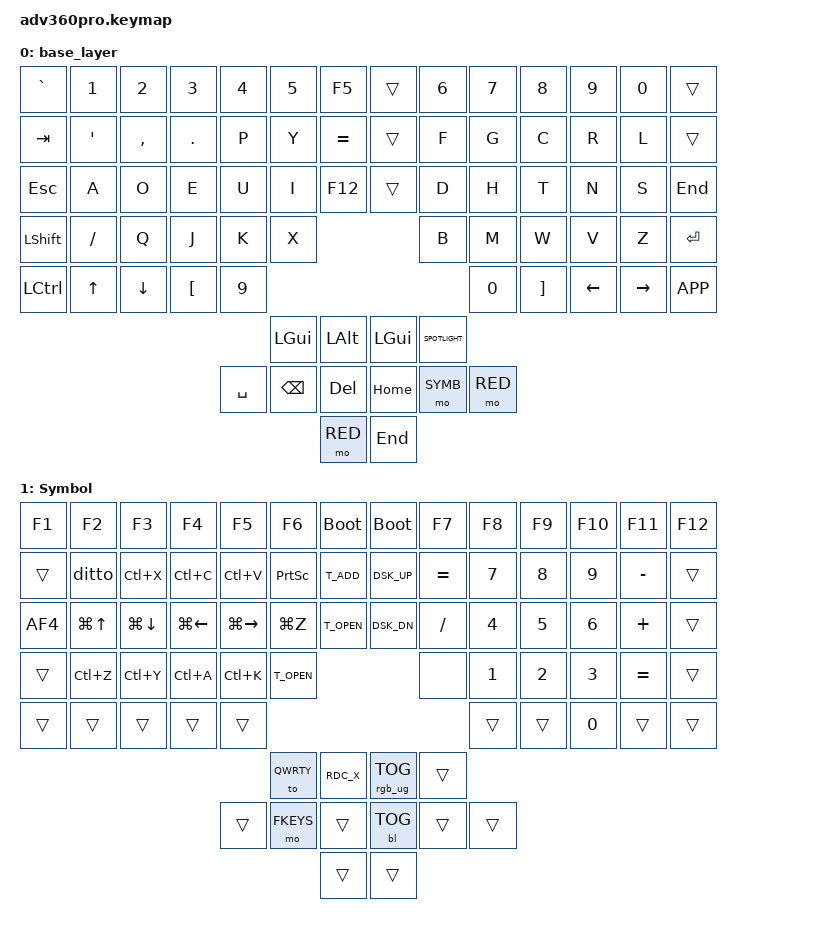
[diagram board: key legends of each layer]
#include <behaviors.dtsi>
#include <dt-bindings/zmk/keys.h>
#include <dt-bindings/zmk/bt.h>
#include <dt-bindings/zmk/outputs.h>
#include <dt-bindings/zmk/rgb.h>
#include <dt-bindings/zmk/backlight.h>

/* definitions for mouse layer */
#include "mouse.dtsi"

#define ___ &trans

#define BOOTL &bootloader

#define W_UP &kp LG(UP)
#define W_DWN &kp LG(DOWN)
#define W_LFT &kp LG(LEFT)
#define W_RGT &kp LG(RIGHT)

#define BASE 0
#define RED 1
#define SYMB 2
#define FKEYS 3
#define QWRTY 4

#define QWERTY 0
#define COLEMAK 1
#define KEYPAD 2
#define FN 3
#define MOD 4
#define MS 5

#define RGBTGL &rgb_ug RGB_TOG
#define BTTGL &bl BL_TOG

/ {
    /* remove unused keys from layout and move thumb cluster to bottom */
    chosen {
        zmk,matrix_transform = &urobs_transform;
    };    
    behaviors {
      #include "macros/macros.dtsi"
    };

    keymap {
        compatible = "zmk,keymap";
        base_layer {
            bindings = <
                &kp GRAVE &kp N1    &kp N2    &kp N3    &kp N4    &kp N5    &kp F5         ___       &kp N6    &kp N7    &kp N8    &kp N9    &kp N0    ___
                &kp TAB   &kp SQT   &kp COMMA &kp PERIOD&kp P     &kp Y     &kp EQUAL      ___       &kp F     &kp G     &kp C     &kp R     &kp L     ___
                &kp ESC   &kp A     &kp O     &kp E     &kp U     &kp I     &kp F12        ___       &kp D     &kp H     &kp T     &kp N     &kp S     &kp END
                &kp LSHFT &kp SLASH &kp Q     &kp J     &kp K     &kp X                              &kp B     &kp M     &kp W     &kp V     &kp Z     &kp ENTER
                &kp LCTRL &kp UP    &kp DOWN  &kp LBKT  &kp N9                                                 &kp N0    &kp RBKT  &kp LEFT  &kp RIGHT &kp K_APP
                                                                  &kp LGUI  &kp LALT       &kp LGUI  &SPOTLIGHT
                                                        &kp SPACE &kp BSPC  &kp DEL        &kp HOME  &mo SYMB  &mo RED
                                                                            &mo RED        &kp END
            >;
        };
        Symbol {
            bindings = <
                &kp F1    &kp F2    &kp F3    &kp F4    &kp F5    &kp F6    BOOTL          BOOTL     &kp F7     &kp F8   &kp F9    &kp F10   &kp F11   &kp F12 
                &trans    &ditto    &kp LC(X) &kp LC(C) &kp LC(V) &kp PSCRN &T_ADD         &DSK_UP   &kp EQUAL  &kp N7   &kp N8    &kp N9    &kp MINUS ___
                &AF4      W_UP      W_DWN     W_LFT     W_RGT     &kp LG(Z) &T_OPEN        &DSK_DN   &kp SLASH  &kp N4   &kp N5    &kp N6    &kp PLUS  ___
                &trans    &kp LC(Z) &kp LC(Y) &kp LC(A) &kp LC(K) &T_OPEN                            &none      &kp N1   &kp N2    &kp N3    &kp EQUAL ___
                ___       ___       ___       ___       ___                                                    ___       ___       &kp N0    ___       ___
                                                                  &to QWRTY &RDC_X         RGBTGL    ___
                                                        ___       &mo FKEYS ___            BTTGL     ___       ___
                                                                            ___            ___
            >;
        };
    };

};

